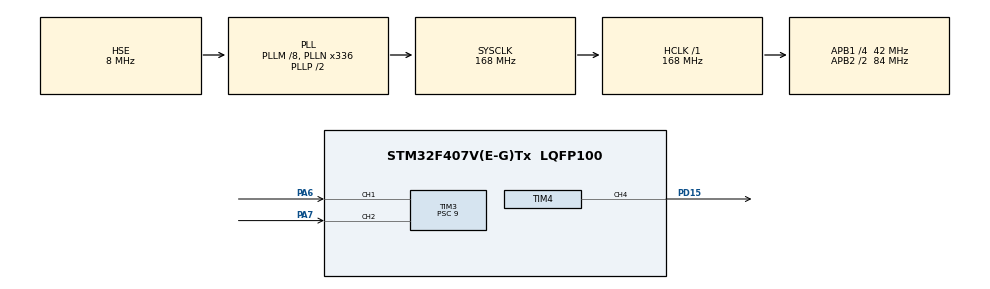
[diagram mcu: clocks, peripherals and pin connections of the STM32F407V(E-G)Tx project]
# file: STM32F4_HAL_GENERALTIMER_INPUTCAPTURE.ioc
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Dma.Request0=TIM3_CH1/TRIG
Dma.Request1=TIM3_CH2
Dma.TIM3_CH1/TRIG.0.Direction=DMA_PERIPH_TO_MEMORY
Dma.TIM3_CH1/TRIG.0.FIFOMode=DMA_FIFOMODE_DISABLE
Dma.TIM3_CH1/TRIG.0.Instance=DMA1_Stream4
Dma.TIM3_CH1/TRIG.0.MemDataAlignment=DMA_MDATAALIGN_HALFWORD
Dma.TIM3_CH1/TRIG.0.MemInc=DMA_MINC_ENABLE
Dma.TIM3_CH1/TRIG.0.Mode=DMA_CIRCULAR
Dma.TIM3_CH1/TRIG.0.PeriphDataAlignment=DMA_PDATAALIGN_HALFWORD
Dma.TIM3_CH1/TRIG.0.PeriphInc=DMA_PINC_DISABLE
Dma.TIM3_CH1/TRIG.0.Priority=DMA_PRIORITY_LOW
Dma.TIM3_CH2.1.Direction=DMA_PERIPH_TO_MEMORY
Dma.TIM3_CH2.1.FIFOMode=DMA_FIFOMODE_DISABLE
Dma.TIM3_CH2.1.Instance=DMA1_Stream5
Dma.TIM3_CH2.1.MemDataAlignment=DMA_MDATAALIGN_HALFWORD
Dma.TIM3_CH2.1.MemInc=DMA_MINC_ENABLE
Dma.TIM3_CH2.1.Mode=DMA_CIRCULAR
Dma.TIM3_CH2.1.PeriphDataAlignment=DMA_PDATAALIGN_HALFWORD
Dma.TIM3_CH2.1.PeriphInc=DMA_PINC_DISABLE
Dma.TIM3_CH2.1.Priority=DMA_PRIORITY_LOW
Mcu.Family=STM32F4
Mcu.Name=STM32F407V(E-G)Tx
Mcu.Package=LQFP100
NVIC.DMA1_Stream4_IRQn=true\:0\:0\:false\:false\:true\:false
NVIC.DMA1_Stream5_IRQn=true\:0\:0\:false\:false\:true\:false
NVIC.PriorityGroup=NVIC_PRIORITYGROUP_0
NVIC.TIM3_IRQn=true\:0\:0\:false\:false\:true\:true
PA6.Signal=S_TIM3_CH1
PA7.Signal=S_TIM3_CH2
PD15.Signal=S_TIM4_CH4
PH0-OSC_IN.Mode=HSE-External-Oscillator
PH0-OSC_IN.Signal=RCC_OSC_IN
PH1-OSC_OUT.Mode=HSE-External-Oscillator
PH1-OSC_OUT.Signal=RCC_OSC_OUT
ProjectManager.HeapSize=0x200
ProjectManager.StackSize=0x400
ProjectManager.TargetToolchain=TrueSTUDIO
RCC.48MHZClocksFreq_Value=48000000
RCC.AHBFreq_Value=168000000
RCC.APB1CLKDivider=RCC_HCLK_DIV4
RCC.APB1Freq_Value=42000000
RCC.APB1TimFreq_Value=84000000
RCC.APB2CLKDivider=RCC_HCLK_DIV2
RCC.APB2Freq_Value=84000000
RCC.APB2TimFreq_Value=168000000
RCC.CortexFreq_Value=168000000
RCC.HCLKFreq_Value=168000000
RCC.HSE_VALUE=8000000
RCC.HSI_VALUE=16000000
RCC.LSE_VALUE=32768
RCC.PLLM=8
RCC.PLLN=336
RCC.PLLQ=7
RCC.PLLSourceVirtual=RCC_PLLSOURCE_HSE
RCC.SYSCLKFreq_VALUE=168000000
RCC.SYSCLKSource=RCC_SYSCLKSOURCE_PLLCLK
RCC.VCOOutputFreq_Value=336000000
SH.S_TIM3_CH1.0=TIM3_CH1,Input_Capture1_from_TI1
SH.S_TIM3_CH2.0=TIM3_CH2,Input_Capture2_from_TI2
SH.S_TIM4_CH4.0=TIM4_CH4,PWM Generation4 CH4
TIM3.Channel-Input_Capture1_from_TI1=TIM_CHANNEL_1
TIM3.Channel-Input_Capture2_from_TI2=TIM_CHANNEL_2
TIM3.ICFilter_CH1=15
TIM3.ICFilter_CH2=15
TIM3.ICPolarity_CH2=TIM_INPUTCHANNELPOLARITY_FALLING
TIM3.Period=65535
TIM3.Prescaler=9
TIM4.Channel-PWM\ Generation4\ CH4=TIM_CHANNEL_4
TIM4.Period=499
TIM4.Prescaler=83
TIM4.Pulse-PWM\ Generation4\ CH4=249
VP_TIM3_VS_ClockSourceINT.Mode=Internal
VP_TIM4_VS_ClockSourceINT.Mode=Internal
board=STM32F4DISCOVERY

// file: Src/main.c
/**
  ******************************************************************************
  * @file           : main.c
  * @brief          : Main program body
  ******************************************************************************
  ** This notice applies to any and all portions of this file
  * that are not between comment pairs USER CODE BEGIN and
  * USER CODE END. Other portions of this file, whether
  * inserted by the user or by software development tools
  * are owned by their respective copyright owners.
  *
  * COPYRIGHT(c) 2019 STMicroelectronics
  *
  * Redistribution and use in source and binary forms, with or without modification,
  * are permitted provided that the following conditions are met:
  *   1. Redistributions of source code must retain the above copyright notice,
  *      this list of conditions and the following disclaimer.
  *   2. Redistributions in binary form must reproduce the above copyright notice,
  *      this list of conditions and the following disclaimer in the documentation
  *      and/or other materials provided with the distribution.
  *   3. Neither the name of STMicroelectronics nor the names of its contributors
  *      may be used to endorse or promote products derived from this software
  *      without specific prior written permission.
  *
  * THIS SOFTWARE IS PROVIDED BY THE COPYRIGHT HOLDERS AND CONTRIBUTORS "AS IS"
  * AND ANY EXPRESS OR IMPLIED WARRANTIES, INCLUDING, BUT NOT LIMITED TO, THE
  * IMPLIED WARRANTIES OF MERCHANTABILITY AND FITNESS FOR A PARTICULAR PURPOSE ARE
  * DISCLAIMED. IN NO EVENT SHALL THE COPYRIGHT HOLDER OR CONTRIBUTORS BE LIABLE
  * FOR ANY DIRECT, INDIRECT, INCIDENTAL, SPECIAL, EXEMPLARY, OR CONSEQUENTIAL
  * DAMAGES (INCLUDING, BUT NOT LIMITED TO, PROCUREMENT OF SUBSTITUTE GOODS OR
  * SERVICES; LOSS OF USE, DATA, OR PROFITS; OR BUSINESS INTERRUPTION) HOWEVER
  * CAUSED AND ON ANY THEORY OF LIABILITY, WHETHER IN CONTRACT, STRICT LIABILITY,
  * OR TORT (INCLUDING NEGLIGENCE OR OTHERWISE) ARISING IN ANY WAY OUT OF THE USE
  * OF THIS SOFTWARE, EVEN IF ADVISED OF THE POSSIBILITY OF SUCH DAMAGE.
  *
  ******************************************************************************
  */
#include "main.h"
#include "stm32f4xx_hal.h"

/* USER CODE BEGIN Includes */
#include <stdbool.h>

/* USER CODE END Includes */

TIM_HandleTypeDef htim3;
TIM_HandleTypeDef htim4;
DMA_HandleTypeDef hdma_tim3_ch1_trig;
DMA_HandleTypeDef hdma_tim3_ch2;

/* USER CODE BEGIN PV */
/* Private variables ---------------------------------------------------------*/

/* USER CODE END PV */

void SystemClock_Config(void);
static void MX_GPIO_Init(void);
static void MX_DMA_Init(void);
static void MX_TIM3_Init(void);
static void MX_TIM4_Init(void);

void HAL_TIM_MspPostInit(TIM_HandleTypeDef *htim);

/* USER CODE BEGIN PFP */
/* Private function prototypes -----------------------------------------------*/

/* USER CODE END PFP */

/* USER CODE BEGIN 0 */
uint16_t capture1[2];
uint16_t capture2[2];
uint32_t period, active, freq, duty;
bool ch1done = false;
bool ch2done = false;

void HAL_TIM_IC_CaptureCallback(TIM_HandleTypeDef *htim)
{
  if(htim->Instance == TIM3 && htim->Channel == HAL_TIM_ACTIVE_CHANNEL_1)
  {
    ch1done = true;
  }

  if(htim->Instance == TIM3 && htim->Channel == HAL_TIM_ACTIVE_CHANNEL_2)
  {
    ch2done = true;
  }
}

/* USER CODE END 0 */

int main(void)
{

  /* MCU Configuration----------------------------------------------------------*/

  /* Reset of all peripherals, Initializes the Flash interface and the Systick. */
  HAL_Init();

  /* Configure the system clock */
  SystemClock_Config();

  /* Initialize all configured peripherals */
  MX_GPIO_Init();
  MX_DMA_Init();
  MX_TIM3_Init();
  MX_TIM4_Init();
  /* USER CODE BEGIN 2 */
  HAL_TIM_IC_Start_DMA(&htim3, TIM_CHANNEL_1, (uint32_t *)capture1, 2);
  htim3.State = HAL_TIM_STATE_READY;
  HAL_TIM_IC_Start_DMA(&htim3, TIM_CHANNEL_2, (uint32_t *)capture2, 2);

  HAL_TIM_PWM_Start(&htim4, TIM_CHANNEL_4);

  /* USER CODE END 2 */

  /* Infinite loop */
  while (1)
  {

  /* USER CODE BEGIN 3 */
    if(ch1done)
    {
      if(capture1[0] > capture1[1])
      {
        period = htim3.Instance->ARR + capture1[1] - capture1[0];
      }
      else
      {
        period = capture1[1] - capture1[0];
      }

      freq = (HAL_RCC_GetPCLK1Freq() * 2) / (htim3.Instance->PSC + 1);  //84000000
      freq = freq / period;

      ch1done = false;
    }

    if(ch2done)
    {
      if(capture2[0] >= capture1[0] && capture2[0] <= capture1[1])
      {
        active = capture2[0] - capture1[0];
      }
      else if(capture2[1] >= capture1[0] && capture2[1] <= capture1[1])
      {
        active = capture2[1] - capture1[0];
      }

      duty = active * 100 / period;
      ch2done = false;
    }
  }
  /* USER CODE END 3 */

}

void SystemClock_Config(void)
{

  RCC_OscInitTypeDef RCC_OscInitStruct;
  RCC_ClkInitTypeDef RCC_ClkInitStruct;

    /**Configure the main internal regulator output voltage
    */
  __HAL_RCC_PWR_CLK_ENABLE();

  __HAL_PWR_VOLTAGESCALING_CONFIG(PWR_REGULATOR_VOLTAGE_SCALE1);

    /**Initializes the CPU, AHB and APB busses clocks
    */
  RCC_OscInitStruct.OscillatorType = RCC_OSCILLATORTYPE_HSE;
  RCC_OscInitStruct.HSEState = RCC_HSE_ON;
  RCC_OscInitStruct.PLL.PLLState = RCC_PLL_ON;
  RCC_OscInitStruct.PLL.PLLSource = RCC_PLLSOURCE_HSE;
  RCC_OscInitStruct.PLL.PLLM = 8;
  RCC_OscInitStruct.PLL.PLLN = 336;
  RCC_OscInitStruct.PLL.PLLP = RCC_PLLP_DIV2;
  RCC_OscInitStruct.PLL.PLLQ = 7;
  if (HAL_RCC_OscConfig(&RCC_OscInitStruct) != HAL_OK)
  {
    _Error_Handler(__FILE__, __LINE__);
  }

    /**Initializes the CPU, AHB and APB busses clocks
    */
  RCC_ClkInitStruct.ClockType = RCC_CLOCKTYPE_HCLK|RCC_CLOCKTYPE_SYSCLK
                              |RCC_CLOCKTYPE_PCLK1|RCC_CLOCKTYPE_PCLK2;
  RCC_ClkInitStruct.SYSCLKSource = RCC_SYSCLKSOURCE_PLLCLK;
  RCC_ClkInitStruct.AHBCLKDivider = RCC_SYSCLK_DIV1;
  RCC_ClkInitStruct.APB1CLKDivider = RCC_HCLK_DIV4;
  RCC_ClkInitStruct.APB2CLKDivider = RCC_HCLK_DIV2;

  if (HAL_RCC_ClockConfig(&RCC_ClkInitStruct, FLASH_LATENCY_5) != HAL_OK)
  {
    _Error_Handler(__FILE__, __LINE__);
  }

    /**Configure the Systick interrupt time
    */
  HAL_SYSTICK_Config(HAL_RCC_GetHCLKFreq()/1000);

    /**Configure the Systick
    */
  HAL_SYSTICK_CLKSourceConfig(SYSTICK_CLKSOURCE_HCLK);

  /* SysTick_IRQn interrupt configuration */
  HAL_NVIC_SetPriority(SysTick_IRQn, 0, 0);
}

/* TIM3 init function */
static void MX_TIM3_Init(void)
{

  TIM_ClockConfigTypeDef sClockSourceConfig;
  TIM_MasterConfigTypeDef sMasterConfig;
  TIM_IC_InitTypeDef sConfigIC;

  htim3.Instance = TIM3;
  htim3.Init.Prescaler = 9;
  htim3.Init.CounterMode = TIM_COUNTERMODE_UP;
  htim3.Init.Period = 65535;
  htim3.Init.ClockDivision = TIM_CLOCKDIVISION_DIV1;
  if (HAL_TIM_Base_Init(&htim3) != HAL_OK)
  {
    _Error_Handler(__FILE__, __LINE__);
  }

  sClockSourceConfig.ClockSource = TIM_CLOCKSOURCE_INTERNAL;
  if (HAL_TIM_ConfigClockSource(&htim3, &sClockSourceConfig) != HAL_OK)
  {
    _Error_Handler(__FILE__, __LINE__);
  }

  if (HAL_TIM_IC_Init(&htim3) != HAL_OK)
  {
    _Error_Handler(__FILE__, __LINE__);
  }

  sMasterConfig.MasterOutputTrigger = TIM_TRGO_RESET;
  sMasterConfig.MasterSlaveMode = TIM_MASTERSLAVEMODE_DISABLE;
  if (HAL_TIMEx_MasterConfigSynchronization(&htim3, &sMasterConfig) != HAL_OK)
  {
    _Error_Handler(__FILE__, __LINE__);
  }

  sConfigIC.ICPolarity = TIM_INPUTCHANNELPOLARITY_RISING;
  sConfigIC.ICSelection = TIM_ICSELECTION_DIRECTTI;
  sConfigIC.ICPrescaler = TIM_ICPSC_DIV1;
  sConfigIC.ICFilter = 15;
  if (HAL_TIM_IC_ConfigChannel(&htim3, &sConfigIC, TIM_CHANNEL_1) != HAL_OK)
  {
    _Error_Handler(__FILE__, __LINE__);
  }

  sConfigIC.ICPolarity = TIM_INPUTCHANNELPOLARITY_FALLING;
  if (HAL_TIM_IC_ConfigChannel(&htim3, &sConfigIC, TIM_CHANNEL_2) != HAL_OK)
  {
    _Error_Handler(__FILE__, __LINE__);
  }

}

/* TIM4 init function */
static void MX_TIM4_Init(void)
{

  TIM_ClockConfigTypeDef sClockSourceConfig;
  TIM_MasterConfigTypeDef sMasterConfig;
  TIM_OC_InitTypeDef sConfigOC;

  htim4.Instance = TIM4;
  htim4.Init.Prescaler = 83;
  htim4.Init.CounterMode = TIM_COUNTERMODE_UP;
  htim4.Init.Period = 499;
  htim4.Init.ClockDivision = TIM_CLOCKDIVISION_DIV1;
  if (HAL_TIM_Base_Init(&htim4) != HAL_OK)
  {
    _Error_Handler(__FILE__, __LINE__);
  }

  sClockSourceConfig.ClockSource = TIM_CLOCKSOURCE_INTERNAL;
  if (HAL_TIM_ConfigClockSource(&htim4, &sClockSourceConfig) != HAL_OK)
  {
    _Error_Handler(__FILE__, __LINE__);
  }

  if (HAL_TIM_PWM_Init(&htim4) != HAL_OK)
  {
    _Error_Handler(__FILE__, __LINE__);
  }

  sMasterConfig.MasterOutputTrigger = TIM_TRGO_RESET;
  sMasterConfig.MasterSlaveMode = TIM_MASTERSLAVEMODE_DISABLE;
  if (HAL_TIMEx_MasterConfigSynchronization(&htim4, &sMasterConfig) != HAL_OK)
  {
    _Error_Handler(__FILE__, __LINE__);
  }

  sConfigOC.OCMode = TIM_OCMODE_PWM1;
  sConfigOC.Pulse = 249;
  sConfigOC.OCPolarity = TIM_OCPOLARITY_HIGH;
  sConfigOC.OCFastMode = TIM_OCFAST_DISABLE;
  if (HAL_TIM_PWM_ConfigChannel(&htim4, &sConfigOC, TIM_CHANNEL_4) != HAL_OK)
  {
    _Error_Handler(__FILE__, __LINE__);
  }

  HAL_TIM_MspPostInit(&htim4);

}

static void MX_DMA_Init(void)
{
  /* DMA controller clock enable */
  __HAL_RCC_DMA1_CLK_ENABLE();

  /* DMA interrupt init */
  /* DMA1_Stream4_IRQn interrupt configuration */
  HAL_NVIC_SetPriority(DMA1_Stream4_IRQn, 0, 0);
  HAL_NVIC_EnableIRQ(DMA1_Stream4_IRQn);
  /* DMA1_Stream5_IRQn interrupt configuration */
  HAL_NVIC_SetPriority(DMA1_Stream5_IRQn, 0, 0);
  HAL_NVIC_EnableIRQ(DMA1_Stream5_IRQn);

}

/** Configure pins as
        * Analog
        * Input
        * Output
        * EVENT_OUT
        * EXTI
*/
static void MX_GPIO_Init(void)
{

  /* GPIO Ports Clock Enable */
  __HAL_RCC_GPIOH_CLK_ENABLE();
  __HAL_RCC_GPIOA_CLK_ENABLE();
  __HAL_RCC_GPIOD_CLK_ENABLE();

}

void _Error_Handler(char *file, int line)
{
  while(1)
  {
  }
}

/************************ (C) COPYRIGHT STMicroelectronics *****END OF FILE****/
